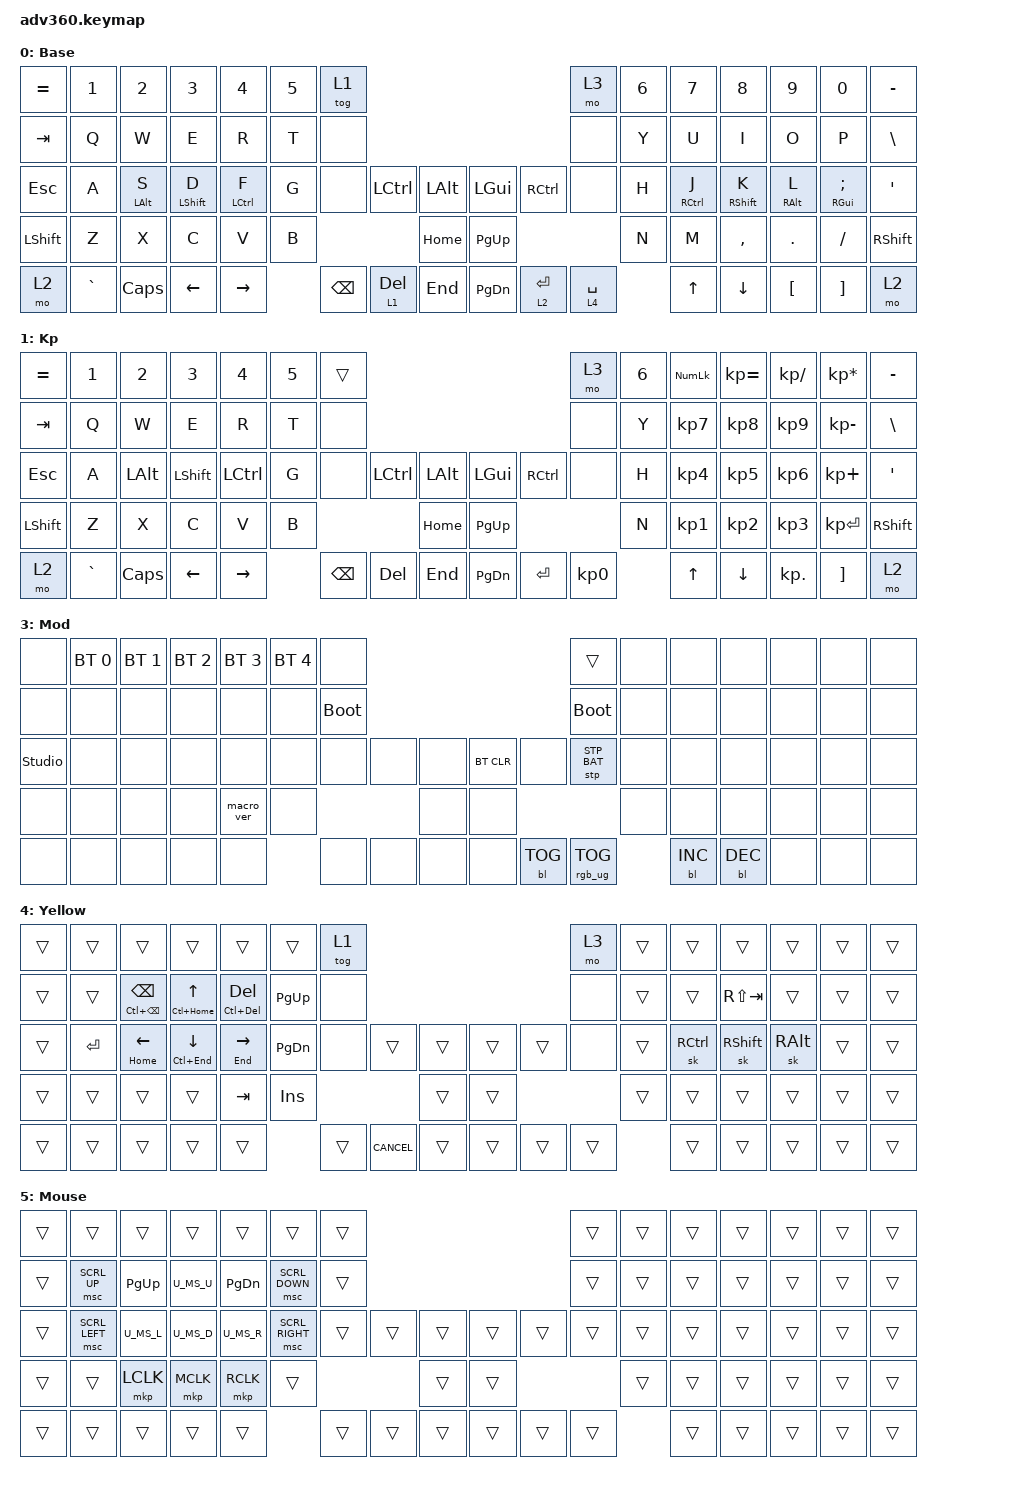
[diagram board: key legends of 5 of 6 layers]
#define ZMK_POINTING_DEFAULT_MOVE_VAL 1500 // 600
#define ZMK_POINTING_DEFAULT_SCRL_VAL 20   // 10
#include <dt-bindings/zmk/stp.h>
#include <behaviors.dtsi>
#include <zmk-helpers/helper.h>
#include "keys_adv360.h"
#include <dt-bindings/zmk/backlight.h>
#include <dt-bindings/zmk/bt.h>
#include <dt-bindings/zmk/keys.h>
#include <dt-bindings/zmk/rgb.h>

#define BASE 0
#define KP   1
#define FN   2
#define MOD  3
#define NAV  4
#define MOUSE 5

#define XXX &none
#define ___ &trans

/* Global defaults */

#define QUICK_TAP_MS 175

#include "mouse.dtsi"

&sl { ignore-modifiers; };

&lt {
    flavor = "balanced";
    quick-tap-ms = <QUICK_TAP_MS>;
    tapping-term-ms = <200>;
};

&sk {
    release-after-ms = <900>;
    quick-release;
};

/ {
    behaviors {
        #include "macros.dtsi"
      #include "version.dtsi"

        hmr: homerow_mods_right {
            compatible = "zmk,behavior-hold-tap";
            label = "HOMEROW_MODS_RIGHT";
            #binding-cells = <2>;
            tapping-term-ms = <250>;
            quick-tap-ms = <175>;
            flavor = "balanced";
            bindings = <&kp>, <&kp>;

            require-prior-idle-ms = <190>;
            hold-trigger-key-positions = <0 1 2 3 4 5 6 14 15 16 17 18 19 20 28 29 30 31 32 33 34 35 36 46 47 48 49 50 51 52 60 61 62 63 64 65 66 67>;
            hold-trigger-on-release;
        };

        hml: hml {
            compatible = "zmk,behavior-hold-tap";
            label = "HML";
            #binding-cells = <2>;
            tapping-term-ms = <250>;
            quick-tap-ms = <175>;
            flavor = "balanced";
            bindings = <&kp>, <&kp>;

            require-prior-idle-ms = <190>;
            hold-trigger-key-positions = <37 7 8 9 10 11 12 13 21 22 23 24 25 26 27 37 38 39 40 41 42 43 44 45 53 54 55 56 57 58 59 68 69 70 71 72 73 74 75>;
            hold-trigger-on-release;
        };

        lpar: lpar {
            compatible = "zmk,behavior-hold-tap";
            label = "LPAR";
            #binding-cells = <2>;
            tapping-term-ms = <250>;
            quick-tap-ms = <175>;
            flavor = "balanced";
            bindings = <&kp>, <&lparen_lt>;

            require-prior-idle-ms = <190>;
            hold-trigger-on-release;
            hold-trigger-key-positions = <0 1 2 3 4 5 6 14 15 16 17 18 19 20 28 29 30 31 32 33 34 35 36 46 47 48 49 50 51 52 60 61 62 63 64 65 66 67>;
        };

        lparen_lt: lparen_lt {
            compatible = "zmk,behavior-mod-morph";
            label = "LPAREN_LT";
            bindings = <&kp LEFT_PARENTHESIS>, <&kp LESS_THAN>;

            #binding-cells = <0>;
            mods = <(MOD_RSFT|MOD_LSFT)>;
        };

        rpar: rpar {
            compatible = "zmk,behavior-hold-tap";
            label = "RPAR";
            #binding-cells = <2>;
            tapping-term-ms = <250>;
            quick-tap-ms = <175>;
            flavor = "balanced";
            bindings = <&kp>, <&rpar_gt>;

            require-prior-idle-ms = <190>;
            hold-trigger-on-release;
            hold-trigger-key-positions = <0 1 2 3 4 5 6 14 15 16 17 18 19 20 28 29 30 31 32 33 34 35 36 46 47 48 49 50 51 52 60 61 62 63 64 65 66 67>;
        };

        rpar_gt: rpar_gt {
            compatible = "zmk,behavior-mod-morph";
            label = "RPAR_GT";
            bindings = <&kp RPAR>, <&kp GT>;

            #binding-cells = <0>;
            mods = <(MOD_RSFT|MOD_LSFT)>;
        };
    };

    combos {
        compatible = "zmk,combos";

        lpar_lt {
            bindings = <&lpar LCTRL LEFT_PARENTHESIS>;
            key-positions = <30 31>;
            require-prior-idle-ms = <150>;
            layers = <0 1 2>;
        };

        rpar_gt {
            bindings = <&rpar RIGHT_ALT LEFT_PARENTHESIS>;
            key-positions = <32 31>;
            require-prior-idle-ms = <150>;
            layers = <0 2 1>;
        };

        lbkt_lbrc {
            bindings = <&hml LEFT_BRACKET LEFT_BRACKET>;
            key-positions = <49 48>;
            require-prior-idle-ms = <150>;
            layers = <0 1 2>;
        };

        rbkt_rbrc {
            bindings = <&hml RIGHT_BRACKET RIGHT_BRACKET>;
            key-positions = <50 49>;
            require-prior-idle-ms = <150>;
            layers = <0 2 1>;
        };

        slash {
            bindings = <&hmr SLASH SLASH>;
            key-positions = <42 56>;
            require-prior-idle-ms = <150>;
            layers = <0 2 1>;
        };

        astrk {
            bindings = <&hmr ASTRK ASTRK>;
            key-positions = <42 24>;
            layers = <0 2 1>;
            require-prior-idle-ms = <150>;
        };

        minus {
            bindings = <&hmr MINUS MINUS>;
            key-positions = <41 55>;
            layers = <0 1 2>;
            require-prior-idle-ms = <150>;
        };

        plus {
            bindings = <&hmr PLUS PLUS>;
            key-positions = <23 41>;
            layers = <0 2 1>;
            require-prior-idle-ms = <150>;
        };

        undr {
            bindings = <&hmr UNDERSCORE UNDER>;
            key-positions = <54 40>;
            require-prior-idle-ms = <150>;
            layers = <0 1 2>;
        };

        carrot {
            bindings = <&hmr CARET CARET>;
            key-positions = <40 22>;
            require-prior-idle-ms = <150>;
            layers = <0 1 2>;
        };

        and {
            bindings = <&hmr AMPERSAND AMPERSAND>;
            key-positions = <44 26>;
            require-prior-idle-ms = <150>;
            layers = <0 1 2>;
        };

        pipe {
            bindings = <&hmr PIPE PIPE>;
            key-positions = <44 58>;
            require-prior-idle-ms = <150>;
            layers = <0 1 2>;
        };

        percent {
            bindings = <&hml PERCENT PERCENT>;
            key-positions = <33 19>;
            require-prior-idle-ms = <150>;
            layers = <0 1 2>;
        };

        dash {
            bindings = <&hml TILDE TILDE>;
            key-positions = <33 51>;
            require-prior-idle-ms = <150>;
            layers = <0 1 2>;
        };

        equal {
            bindings = <&hml EQUAL EQUAL>;
            key-positions = <32 50>;
            require-prior-idle-ms = <150>;
            layers = <0 1 2>;
        };

        dollar {
            bindings = <&hml DLLR DLLR>;
            key-positions = <32 18>;
            require-prior-idle-ms = <150>;
            layers = <0 1 2>;
        };

        bkslsh {
            bindings = <&hml BSLH BSLH>;
            key-positions = <31 49>;
            require-prior-idle-ms = <150>;
            layers = <0 1 2>;
        };

        dot {
            bindings = <&hml PERIOD PERIOD>;
            key-positions = <48 30>;
            require-prior-idle-ms = <150>;
            layers = <0 1 2>;
        };

        at {
            bindings = <&hml AT AT>;
            key-positions = <30 16>;
            require-prior-idle-ms = <150>;
            layers = <0 1 2>;
        };

        hash {
            bindings = <&hml HASH HASH>;
            key-positions = <17 31>;
            require-prior-idle-ms = <150>;
            layers = <0 1 2>;
        };

        tab {
            bindings = <&hmr TAB TAB>;
            key-positions = <42 41>;
            require-prior-idle-ms = <150>;
            layers = <0 1 2>;
        };

        esc {
            bindings = <&hmr ESCAPE ESCAPE>;
            key-positions = <42 43>;
            require-prior-idle-ms = <150>;
            layers = <0 1 2>;
        };

        mp {
            bindings = <&mkp LCLK>;
            key-positions = <23 24>;
            require-prior-idle-ms = <150>;
            layers = <0 1 2>;
        };

        mouse {
            bindings = <&tog 5>;
            key-positions = <23 25>;
        };

        mouse-to-base {
            bindings = <&to 0>;
            key-positions = <23 25>;
            layers = <5>;
        };
    };

    keymap {
        compatible = "zmk,keymap";

        default_layer {
            display-name = "Base";
            bindings = <
&kp EQUAL  &kp N1     &kp N2           &kp N3             &kp N4        &kp N5  &tog 1                                                     &mo 3        &kp N6  &kp N7        &kp N8              &kp N9            &kp N0               &kp MINUS
&kp TAB    &kp Q      &kp W            &kp E              &kp R         &kp T   &none                                                      &none        &kp Y   &kp U         &kp I               &kp O             &kp P                &kp BSLH
&kp ESC    &kp A      &hml LEFT_ALT S  &hml LEFT_SHIFT D  &hml LCTRL F  &kp G   &none     &kp LCTRL  &kp LALT      &kp LGUI   &kp RCTRL    &none        &kp H   &hmr RCTRL J  &hmr RIGHT_SHIFT K  &hmr RIGHT_ALT L  &hmr RIGHT_GUI SEMI  &kp SQT
&kp LSHFT  &kp Z      &kp X            &kp C              &kp V         &kp B                        &kp HOME      &kp PG_UP                            &kp N   &kp M         &kp COMMA           &kp DOT           &kp FSLH             &kp RSHFT
&mo 2      &kp GRAVE  &kp CAPS         &kp LEFT           &kp RIGHT             &kp BSPC  &lt 1 DEL  &kp END       &kp PG_DN  &lt 2 ENTER  &lt 4 SPACE          &kp UP        &kp DOWN            &kp LBKT          &kp RBKT             &mo 2
            >;
        };

        keypad {
            display-name = "Kp";
            bindings = <
&kp EQUAL  &kp N1     &kp N2        &kp N3          &kp N4            &kp N5  &trans                                                   &mo 3      &kp N6  &kp KP_NUM  &kp KP_EQUAL  &kp KP_DIVIDE  &kp KP_MULTIPLY  &kp MINUS
&kp TAB    &kp Q      &kp W         &kp E           &kp R             &kp T   &none                                                    &none      &kp Y   &kp KP_N7   &kp KP_N8     &kp KP_N9      &kp KP_MINUS     &kp BSLH
&kp ESC    &kp A      &kp LEFT_ALT  &kp LEFT_SHIFT  &kp LEFT_CONTROL  &kp G   &none     &kp LCTRL  &kp LALT      &kp LGUI   &kp RCTRL  &none      &kp H   &kp KP_N4   &kp KP_N5     &kp KP_N6      &kp KP_PLUS      &kp SQT
&kp LSHFT  &kp Z      &kp X         &kp C           &kp V             &kp B                        &kp HOME      &kp PG_UP                        &kp N   &kp KP_N1   &kp KP_N2     &kp KP_N3      &kp KP_ENTER     &kp RSHFT
&mo 2      &kp GRAVE  &kp CAPS      &kp LEFT        &kp RIGHT                 &kp BSPC  &kp DEL    &kp END       &kp PG_DN  &kp ENTER  &kp KP_N0          &kp UP      &kp DOWN      &kp KP_DOT     &kp RBKT         &mo 2
            >;
        };

        fn {
            display-name = "Fn";
            bindings = <
&kp F1  &kp F2  &kp F3                      &kp F4                &kp F5                    &kp F6             &tog 1                                      &mo 3   &kp F7  &kp F8         &kp F9               &kp F10            &kp F11  &kp F12
&trans  &trans  &kp C_PREVIOUS              &kp C_VOLUME_UP       &kp C_NEXT                &trans             &none                                       &none   &trans  &kp F7         &kp F8               &kp F9             &trans   &trans
&trans  &trans  &hml LEFT_ALT LG(LC(LEFT))  &hml LSHIFT C_VOL_DN  &hml LCTRL LG(LC(RIGHT))  &trans             &none   &trans  &trans      &trans  &trans  &none   &trans  &hmr RCTRL F4  &hmr RIGHT_SHIFT F5  &hmr RIGHT_ALT F6  &trans   &trans
&trans  &trans  &trans                      &kp LA(GRAVE)         &kp LG(LC(LS(Q)))         &kp LS(LC(LG(A)))                  &trans      &trans                  &trans  &kp F1         &kp F2               &kp F3             &trans   &trans
&trans  &trans  &trans                      &trans                &trans                                       &trans  &trans  &trans      &trans  &trans  &trans          &trans         &trans               &trans             &trans   &trans
            >;
        };

        mod {
            display-name = "Mod";
            bindings = <
&none           &bt BT_SEL 0  &bt BT_SEL 1  &bt BT_SEL 2  &bt BT_SEL 3  &bt BT_SEL 4  &none                                                  &trans           &none  &none       &none       &none  &none  &none
&none           &none         &none         &none         &none         &none         &bootloader                                            &bootloader      &none  &none       &none       &none  &none  &none
&studio_unlock  &none         &none         &none         &none         &none         &none        &none  &none      &bt BT_CLR  &none       &stp STP_BAT     &none  &none       &none       &none  &none  &none
&none           &none         &none         &none         &macro_ver    &none                             &none      &none                                    &none  &none       &none       &none  &none  &none
&none           &none         &none         &none         &none                       &none        &none  &none      &none       &bl BL_TOG  &rgb_ug RGB_TOG         &bl BL_INC  &bl BL_DEC  &none  &none  &none
            >;
        };

        nav {
            display-name = "Yellow";
            bindings = <
&trans  &trans     &trans                       &trans                 &trans              &trans         &tog 1                                            &mo 3   &trans  &trans     &trans           &trans         &trans  &trans
&trans  &trans     &mt LC(BACKSPACE) BACKSPACE  &mt LC(HOME) UP_ARROW  &mt LC(DELETE) DEL  &kp PAGE_UP    &none                                             &none   &trans  &trans     &kp RS(TAB)      &trans         &trans  &trans
&trans  &kp ENTER  &mt HOME LEFT                &mt LC(END) DOWN       &mt END RIGHT       &kp PAGE_DOWN  &none   &trans        &trans      &trans  &trans  &none   &trans  &sk RCTRL  &sk RIGHT_SHIFT  &sk RIGHT_ALT  &trans  &trans
&trans  &trans     &trans                       &trans                 &kp TAB             &kp INS                              &trans      &trans                  &trans  &trans     &trans           &trans         &trans  &trans
&trans  &trans     &trans                       &trans                 &trans                             &trans  &kp K_CANCEL  &trans      &trans  &trans  &trans          &trans     &trans           &trans         &trans  &trans
            >;
        };

        mouse {
            display-name = "Mouse";
            bindings = <
&trans  &trans          &trans          &trans          &trans           &trans           &trans                                      &trans  &trans  &trans  &trans  &trans  &trans  &trans
&trans  &msc SCRL_UP    &kp PAGE_UP     U_MS_U          &kp PAGE_DOWN    &msc SCRL_DOWN   &trans                                      &trans  &trans  &trans  &trans  &trans  &trans  &trans
&trans  &msc SCRL_LEFT  U_MS_L          U_MS_D          U_MS_R           &msc SCRL_RIGHT  &trans  &trans  &trans      &trans  &trans  &trans  &trans  &trans  &trans  &trans  &trans  &trans
&trans  &trans          &mkp LCLK       &mkp MCLK       &mkp RCLK        &trans                           &trans      &trans                  &trans  &trans  &trans  &trans  &trans  &trans
&trans  &trans          &trans          &trans          &trans                            &trans  &trans  &trans      &trans  &trans  &trans          &trans  &trans  &trans  &trans  &trans
            >;
        };
    };
};
